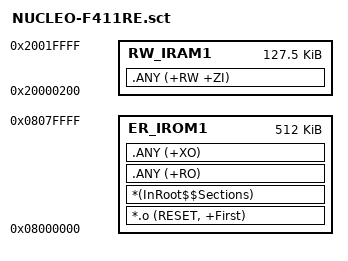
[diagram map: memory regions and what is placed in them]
LR_IROM1 0x08000000 0x00080000  {    ; load region size_region
  ER_IROM1 0x08000000 0x00080000  {  ; load address = execution address
   *.o (RESET, +First)
   *(InRoot$$Sections)
   .ANY (+RO)
   .ANY (+XO)
  }
  RW_IRAM1 0x20000200 0x0001FE00  {  ; RW data - start after AI reserved area
   .ANY (+RW +ZI)
  }
}
